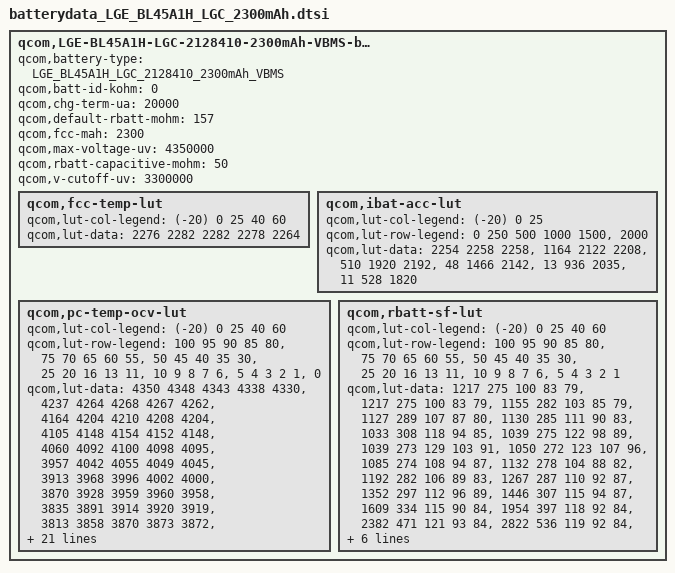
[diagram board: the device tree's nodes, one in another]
/* Copyright (c) 2015, The Linux Foundation. All rights reserved.
 *
 * This program is free software; you can redistribute it and/or modify
 * it under the terms of the GNU General Public License version 2 and
 * only version 2 as published by the Free Software Foundation.
 *
 * This program is distributed in the hope that it will be useful,
 * but WITHOUT ANY WARRANTY; without even the implied warranty of
 * MERCHANTABILITY or FITNESS FOR A PARTICULAR PURPOSE.  See the
 * GNU General Public License for more details.
 */
qcom,LGE-BL45A1H-LGC-2128410-2300mAh-VBMS-batterydata {
	qcom,battery-type = "LGE_BL45A1H_LGC_2128410_2300mAh_VBMS";
	qcom,batt-id-kohm = <0>;
	qcom,chg-term-ua = <20000>;
	qcom,default-rbatt-mohm = <157>;
	qcom,fcc-mah = <2300>;
	qcom,max-voltage-uv = <4350000>;
	qcom,rbatt-capacitive-mohm = <50>;
	qcom,v-cutoff-uv = <3300000>;

	qcom,fcc-temp-lut {
		qcom,lut-col-legend = <(-20) 0 25 40 60>;
		qcom,lut-data = <2276 2282 2282 2278 2264>;
	};

	qcom,ibat-acc-lut {
		qcom,lut-col-legend = <(-20) 0 25>;
		qcom,lut-row-legend = <0 250 500 1000 1500>,
					<2000>;
		qcom,lut-data = <2254 2258 2258>,
				<1164 2122 2208>,
				<510 1920 2192>,
				<48 1466 2142>,
				<13 936 2035>,
				<11 528 1820>;
	};

	qcom,pc-temp-ocv-lut {
		qcom,lut-col-legend = <(-20) 0 25 40 60>;
		qcom,lut-row-legend = <100 95 90 85 80>,
					<75 70 65 60 55>,
					<50 45 40 35 30>,
					<25 20 16 13 11>,
					<10 9 8 7 6>,
					<5 4 3 2 1>,
					<0>;
		qcom,lut-data = <4350 4348 4343 4338 4330>,
				<4237 4264 4268 4267 4262>,
				<4164 4204 4210 4208 4204>,
				<4105 4148 4154 4152 4148>,
				<4060 4092 4100 4098 4095>,
				<3957 4042 4055 4049 4045>,
				<3913 3968 3996 4002 4000>,
				<3870 3928 3959 3960 3958>,
				<3835 3891 3914 3920 3919>,
				<3813 3858 3870 3873 3872>,
				<3795 3830 3838 3839 3838>,
				<3779 3804 3815 3816 3815>,
				<3764 3784 3796 3797 3796>,
				<3746 3767 3781 3782 3780>,
				<3726 3746 3769 3766 3760>,
				<3703 3728 3755 3748 3736>,
				<3676 3714 3734 3728 3714>,
				<3649 3706 3711 3704 3690>,
				<3624 3699 3691 3684 3670>,
				<3606 3692 3684 3676 3664>,
				<3597 3686 3682 3674 3663>,
				<3586 3679 3680 3673 3662>,
				<3572 3670 3677 3670 3658>,
				<3558 3658 3672 3664 3651>,
				<3538 3638 3658 3649 3631>,
				<3512 3610 3626 3612 3594>,
				<3482 3574 3576 3562 3544>,
				<3441 3520 3514 3498 3480>,
				<3377 3444 3428 3413 3396>,
				<3266 3319 3300 3284 3267>,
				<3000 3000 3000 3000 3000>;
	};

	qcom,rbatt-sf-lut {
		qcom,lut-col-legend = <(-20) 0 25 40 60>;
		qcom,lut-row-legend = <100 95 90 85 80>,
					<75 70 65 60 55>,
					<50 45 40 35 30>,
					<25 20 16 13 11>,
					<10 9 8 7 6>,
					<5 4 3 2 1>;
		qcom,lut-data = <1217 275 100 83 79>,
				<1217 275 100 83 79>,
				<1155 282 103 85 79>,
				<1127 289 107 87 80>,
				<1130 285 111 90 83>,
				<1033 308 118 94 85>,
				<1039 275 122 98 89>,
				<1039 273 129 103 91>,
				<1050 272 123 107 96>,
				<1085 274 108 94 87>,
				<1132 278 104 88 82>,
				<1192 282 106 89 83>,
				<1267 287 110 92 87>,
				<1352 297 112 96 89>,
				<1446 307 115 94 87>,
				<1609 334 115 90 84>,
				<1954 397 118 92 84>,
				<2382 471 121 93 84>,
				<2822 536 119 92 84>,
				<3106 568 121 93 85>,
				<3143 549 124 95 87>,
				<3270 546 129 97 88>,
				<3445 554 133 100 88>,
				<3916 582 139 101 89>,
				<4547 618 142 101 87>,
				<5426 669 143 99 87>,
				<6693 741 146 101 89>,
				<8462 851 158 106 92>,
				<11427 1124 177 116 103>,
				<17010 1602 236 155 129>;
	};
};
